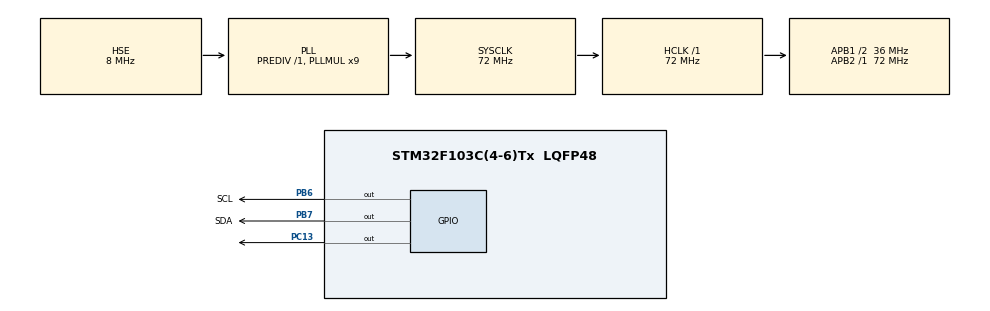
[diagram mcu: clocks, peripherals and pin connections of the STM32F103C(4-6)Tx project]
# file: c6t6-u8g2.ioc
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Mcu.Family=STM32F1
Mcu.Name=STM32F103C(4-6)Tx
Mcu.Package=LQFP48
NVIC.PriorityGroup=NVIC_PRIORITYGROUP_4
PA13.Mode=Serial_Wire
PA13.Signal=SYS_JTMS-SWDIO
PA14.Mode=Serial_Wire
PA14.Signal=SYS_JTCK-SWCLK
PB6.GPIO_Label=SCL
PB6.GPIO_ModeDefaultOutputPP=GPIO_MODE_OUTPUT_OD
PB6.GPIO_PuPd=GPIO_PULLUP
PB6.GPIO_Speed=GPIO_SPEED_FREQ_HIGH
PB6.Signal=GPIO_Output
PB7.GPIO_Label=SDA
PB7.GPIO_ModeDefaultOutputPP=GPIO_MODE_OUTPUT_OD
PB7.GPIO_PuPd=GPIO_PULLUP
PB7.GPIO_Speed=GPIO_SPEED_FREQ_HIGH
PB7.Signal=GPIO_Output
PC13-TAMPER-RTC.Signal=GPIO_Output
PD0-OSC_IN.Mode=HSE-External-Oscillator
PD0-OSC_IN.Signal=RCC_OSC_IN
PD1-OSC_OUT.Mode=HSE-External-Oscillator
PD1-OSC_OUT.Signal=RCC_OSC_OUT
ProjectManager.HeapSize=0x200
ProjectManager.StackSize=0x400
ProjectManager.TargetToolchain=MDK-ARM V5.32
RCC.AHBFreq_Value=72000000
RCC.APB1CLKDivider=RCC_HCLK_DIV2
RCC.APB1Freq_Value=36000000
RCC.APB1TimFreq_Value=72000000
RCC.APB2Freq_Value=72000000
RCC.APB2TimFreq_Value=72000000
RCC.HCLKFreq_Value=72000000
RCC.PLLMUL=RCC_PLL_MUL9
RCC.PLLSourceVirtual=RCC_PLLSOURCE_HSE
RCC.SYSCLKFreq_VALUE=72000000
RCC.SYSCLKSource=RCC_SYSCLKSOURCE_PLLCLK
RCC.USBFreq_Value=72000000
board=custom

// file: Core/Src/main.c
/* USER CODE BEGIN Header */
/**
  ******************************************************************************
  * @file           : main.c
  * @brief          : Main program body
  ******************************************************************************
  * @attention
  *
  * Copyright (c) 2024 STMicroelectronics.
  * All rights reserved.
  *
  * This software is licensed under terms that can be found in the LICENSE file
  * in the root directory of this software component.
  * If no LICENSE file comes with this software, it is provided AS-IS.
  *
  ******************************************************************************
  */
/* USER CODE END Header */
#include "main.h"
#include "gpio.h"

/* USER CODE BEGIN Includes */
#include "u8g2.h"
/* USER CODE END Includes */

void SystemClock_Config(void);
/* USER CODE BEGIN PFP */
uint8_t u8g2_gpio_and_delay_stm32(U8X8_UNUSED u8x8_t *u8x8, U8X8_UNUSED uint8_t msg, U8X8_UNUSED uint8_t arg_int, U8X8_UNUSED void *arg_ptr)
{
	switch(msg){

		//Function which implements a delay, arg_int contains the amount of ms
		case U8X8_MSG_DELAY_MILLI:
		HAL_Delay(arg_int);

		break;
		//Function which delays 10us
		case U8X8_MSG_DELAY_10MICRO:
		for (uint16_t n = 0; n < 320; n++)
		{
			__NOP();
		}

		break;
		//Function which delays 100ns
		case U8X8_MSG_DELAY_100NANO:
		__NOP();

		break;
		//Function to define the logic level of the clockline
		case U8X8_MSG_GPIO_I2C_CLOCK:
			if (arg_int) HAL_GPIO_WritePin(SCL_GPIO_Port, SCL_Pin, GPIO_PIN_SET);
			else HAL_GPIO_WritePin(SCL_GPIO_Port, SCL_Pin, GPIO_PIN_RESET);

		break;
		//Function to define the logic level of the data line to the display
		case U8X8_MSG_GPIO_I2C_DATA:
			if (arg_int) HAL_GPIO_WritePin(SDA_GPIO_Port, SDA_Pin, GPIO_PIN_SET);
			else HAL_GPIO_WritePin(SDA_GPIO_Port, SDA_Pin, GPIO_PIN_RESET);

		break;

		default:
			return 0; //A message was received which is not implemented, return 0 to indicate an error
	}

	return 1; // command processed successfully.
}
/* USER CODE END PFP */

int main(void)
{

  /* USER CODE BEGIN 1 */
	u8g2_t u8g2;

  /* USER CODE END 1 */

  /* MCU Configuration--------------------------------------------------------*/

  /* Reset of all peripherals, Initializes the Flash interface and the Systick. */
  HAL_Init();

  /* Configure the system clock */
  SystemClock_Config();

  /* Initialize all configured peripherals */
  MX_GPIO_Init();
  /* USER CODE BEGIN 2 */

	u8g2_Setup_ssd1306_i2c_128x64_noname_f(&u8g2, U8G2_R0, u8x8_byte_sw_i2c, u8g2_gpio_and_delay_stm32);
	u8g2_InitDisplay(&u8g2); // send init sequence to the display, display is in sleep mode after this,
	u8g2_SetPowerSave(&u8g2, 0); // wake up display
	u8g2_ClearBuffer(&u8g2);
//	HAL_Delay(1000);

  u8g2_DrawLine(&u8g2, 0,0, 127, 63);
	u8g2_DrawLine(&u8g2, 63,0, 63, 63);
	u8g2_DrawLine(&u8g2, 0,31, 127, 31);
	u8g2_DrawLine(&u8g2, 127,0, 0, 63);
  u8g2_SendBuffer(&u8g2);
  /* USER CODE END 2 */

  /* Infinite loop */
  while (1)
  {

  }
}

void SystemClock_Config(void)
{
  RCC_OscInitTypeDef RCC_OscInitStruct = {0};
  RCC_ClkInitTypeDef RCC_ClkInitStruct = {0};

  /** Initializes the RCC Oscillators according to the specified parameters
  * in the RCC_OscInitTypeDef structure.
  */
  RCC_OscInitStruct.OscillatorType = RCC_OSCILLATORTYPE_HSE;
  RCC_OscInitStruct.HSEState = RCC_HSE_ON;
  RCC_OscInitStruct.HSEPredivValue = RCC_HSE_PREDIV_DIV1;
  RCC_OscInitStruct.HSIState = RCC_HSI_ON;
  RCC_OscInitStruct.PLL.PLLState = RCC_PLL_ON;
  RCC_OscInitStruct.PLL.PLLSource = RCC_PLLSOURCE_HSE;
  RCC_OscInitStruct.PLL.PLLMUL = RCC_PLL_MUL9;
  if (HAL_RCC_OscConfig(&RCC_OscInitStruct) != HAL_OK)
  {
    Error_Handler();
  }

  /** Initializes the CPU, AHB and APB buses clocks
  */
  RCC_ClkInitStruct.ClockType = RCC_CLOCKTYPE_HCLK|RCC_CLOCKTYPE_SYSCLK
                              |RCC_CLOCKTYPE_PCLK1|RCC_CLOCKTYPE_PCLK2;
  RCC_ClkInitStruct.SYSCLKSource = RCC_SYSCLKSOURCE_PLLCLK;
  RCC_ClkInitStruct.AHBCLKDivider = RCC_SYSCLK_DIV1;
  RCC_ClkInitStruct.APB1CLKDivider = RCC_HCLK_DIV2;
  RCC_ClkInitStruct.APB2CLKDivider = RCC_HCLK_DIV1;

  if (HAL_RCC_ClockConfig(&RCC_ClkInitStruct, FLASH_LATENCY_2) != HAL_OK)
  {
    Error_Handler();
  }
}

void Error_Handler(void)
{
  __disable_irq();
  while (1)
  {
  }
}
